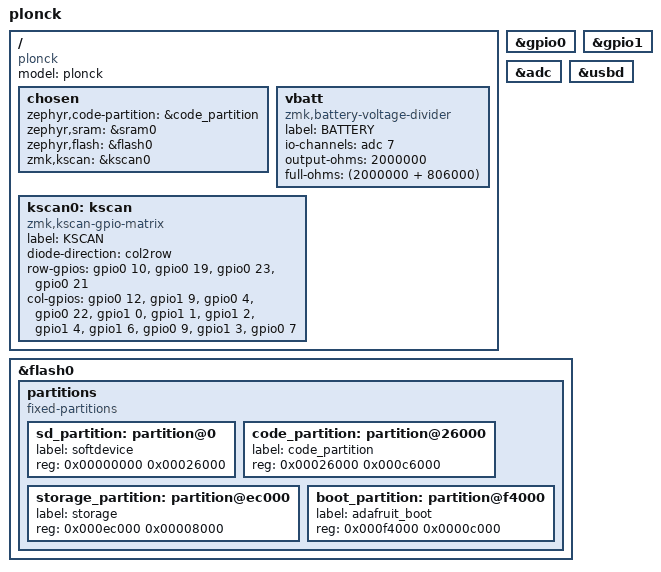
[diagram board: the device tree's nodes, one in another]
/*
 * Copyright (c) 2021 swampmonster
 *
 * SPDX-License-Identifier: MIT
 */

/dts-v1/;
#include <nordic/nrf52840_qiaa.dtsi>
/ {
	model = "plonck";
	compatible = "plonck";

	chosen {
		zephyr,code-partition = &code_partition;
		zephyr,sram = &sram0;
		zephyr,flash = &flash0;
		zmk,kscan = &kscan0;
	};

    vbatt {
		compatible = "zmk,battery-voltage-divider";
		label = "BATTERY";
		io-channels = <&adc 7>;
		output-ohms = <2000000>;
		full-ohms = <(2000000 + 806000)>;
	};

	kscan0: kscan {
		compatible = "zmk,kscan-gpio-matrix";
		label = "KSCAN";

		diode-direction = "col2row";
		row-gpios
			= <&gpio0 10 (GPIO_ACTIVE_HIGH | GPIO_PULL_DOWN)> // 1
			, <&gpio0 19 (GPIO_ACTIVE_HIGH | GPIO_PULL_DOWN)> // 2
			, <&gpio0 23 (GPIO_ACTIVE_HIGH | GPIO_PULL_DOWN)> // 3
			, <&gpio0 21 (GPIO_ACTIVE_HIGH | GPIO_PULL_DOWN)> // 4
			;
		col-gpios
			= <&gpio0 12 GPIO_ACTIVE_HIGH> // 1
			, <&gpio1 9  GPIO_ACTIVE_HIGH> // 2
			, <&gpio0 4  GPIO_ACTIVE_HIGH> // 3
			, <&gpio0 22 GPIO_ACTIVE_HIGH> // 4
			, <&gpio1 0  GPIO_ACTIVE_HIGH> // 5
			, <&gpio1 1  GPIO_ACTIVE_HIGH> // 6
			, <&gpio1 2  GPIO_ACTIVE_HIGH> // 7
			, <&gpio1 4  GPIO_ACTIVE_HIGH> // 8
			, <&gpio1 6  GPIO_ACTIVE_HIGH> // 9
			, <&gpio0 9  GPIO_ACTIVE_HIGH> // 10
			, <&gpio1 3  GPIO_ACTIVE_HIGH> // 11
			, <&gpio0 7  GPIO_ACTIVE_HIGH> // 12
			;
	};
};

&gpio0 {
	status = "okay";
};

&gpio1 {
	status = "okay";
};

&adc {
	status = "okay";
};

&usbd {
	status = "okay";
};

&flash0 {
	/*
	 * For more information, see:
	 * http://docs.zephyrproject.org/latest/devices/dts/flash_partitions.html
	 */
	partitions {
		compatible = "fixed-partitions";
		#address-cells = <1>;
		#size-cells = <1>;

		sd_partition: partition@0 {
			label = "softdevice";
			reg = <0x00000000 0x00026000>;
		};
		code_partition: partition@26000 {
			label = "code_partition";
			reg = <0x00026000 0x000c6000>;
		};

		/*
		 * The flash starting at 0x000ec000 and ending at
		 * 0x000f3fff is reserved for use by the application.
		 */

		/*
		 * Storage partition will be used by FCB/LittleFS/NVS
		 * if enabled.
		 */
		storage_partition: partition@ec000 {
			label = "storage";
			reg = <0x000ec000 0x00008000>;
		};

		boot_partition: partition@f4000 {
			label = "adafruit_boot";
			reg = <0x000f4000 0x0000c000>;
		};
	};
};
